# ATtiny15 register map
Vendor: Atmel; File version: 1.0
CPU: other r0p0, little endian, no MPU, no FPU, 4 interrupt priority bits
Registers are 8-bit, read-write, reset 0x0 unless marked. A register's access mark holds for its fields unless they carry their own. Offsets are from the block's base; lines under a group give offsets from that group; [hi:lo] are bit positions; {n}, {i} and the like mark numbered series; 'fields as' and 'values as' point back to an identical list; <NAME> marks a mode.

## Memory map
0x00800004 ADC size 0x4 — Analog-to-Digital Converter
0x00800008 AC size 0x1 — Analog Comparator
0x00800016 PORTB size 0x3 — I/O Port
0x0080001C EEPROM size 0x3
0x00800021 WDT size 0x1 — Watchdog Timer
0x0080002C TC1 blocks up to offset 0xE — Timer/Counter, 8-bit
0x00800031 CPU blocks up to offset 0xF — CPU Registers
0x00800032 TC0 blocks up to offset 0x8 — Timer/Counter, 8-bit
0x0080003A EXINT size 0x2 — External Interrupts

## Interrupts
0 RESET (CPU) — External Reset, Power-on Reset and Watchdog Reset
1 INT0 (CPU) — External Interrupt 0
2 IO_PINS (CPU) — External Interrupt Request 0
3 TIMER1_COMP (CPU) — Timer/Counter1 Compare Match
4 TIMER1_OVF (CPU) — Timer/Counter1 Overflow
5 TIMER0_OVF (CPU) — Timer/Counter0 Overflow
6 EE_RDY (CPU) — EEPROM Ready
7 ANA_COMP (CPU) — Analog Comparator
8 ADC (CPU) — ADC Conversion Ready

## AC — Analog Comparator
Base 0x00800008
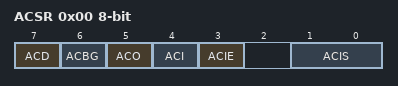
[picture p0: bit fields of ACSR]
0x00 ACSR — Analog Comparator Control And Status Register
  [7] ACD — Analog Comparator Disable
  [6] ACBG — Analog Comparator Bandgap Select
  [5] ACO — Analog Compare Output
  [4] ACI — Analog Comparator Interrupt Flag
  [3] ACIE — Analog Comparator Interrupt Enable
  [1:0] ACIS — Analog Comparator Interrupt Mode Select bits
    0=INTERRUPT_ON_TOGGLE; 2=INTERRUPT_ON_FALLING_EDGE; 3=INTERRUPT_ON_RISING_EDGE

## ADC — Analog-to-Digital Converter
Base 0x00800004
0x00 ADC 16-bit (reset mask 0xFF) — ADC Data Register Bytes
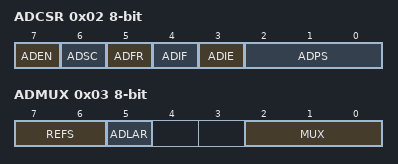
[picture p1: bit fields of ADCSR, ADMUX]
0x02 ADCSR — The ADC Control and Status register
  [7] ADEN — ADC Enable
  [6] ADSC — ADC Start Conversion
  [5] ADFR — ADC Free Running Select
  [4] ADIF — ADC Interrupt Flag
  [3] ADIE — ADC Interrupt Enable
  [2:0] ADPS — ADC Prescaler Select Bits
    1=2; 2=4; 3=8; 4=16; 5=32; 6=64; 7=128
0x03 ADMUX — The ADC multiplexer Selection Register
  [7:6] REFS — Reference Selection Bits
    0=AVCC; 1=AREF; 2=INTERNAL_VOLTAGE_REFERANCE (Internal Voltage Reference); 3=INTERNAL_VOLTAGE_REFERENCE_WITH_EXTERNAL_CAPACITOR_AT_AREF_PIN
  [5] ADLAR — Left Adjust Result
  [2:0] MUX — Analog Channel and Gain Selection Bits

## CPU — CPU Registers
Base 0x00800031
0x00 OSCCAL — Status Register
  [7:0] OSCCAL — Oscillator Calibration
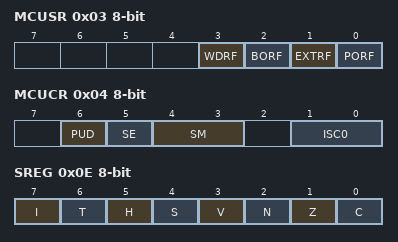
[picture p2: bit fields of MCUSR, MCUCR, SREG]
0x03 MCUSR — MCU Status register
  [3] WDRF — Watchdog Reset Flag
  [2] BORF — Brown-out Reset Flag
  [1] EXTRF — External Reset Flag
  [0] PORF — Power-On Reset Flag
0x04 MCUCR — MCU Control Register
  [6] PUD — Pull-up Disable
  [5] SE — Sleep Enable
  [4:3] SM — Sleep Mode Select Bits
    0=IDLE; 1=ADC (ADC Noise Reduction (If Available)); 2=PDOWN (Power Down)
  [1:0] ISC0 — Interrupt Sense Control 0 bits
    0=LOW_LEVEL_OF_INTX; 1=ANY_LOGICAL_CHANGE_IN_INTX; 2=FALLING_EDGE_OF_INTX; 3=RISING_EDGE_OF_INTX
0x0E SREG — Status Register
  [7] I — Global Interrupt Enable
  [6] T — Bit Copy Storage
  [5] H — Half Carry Flag
  [4] S — Sign Bit
  [3] V — Two's Complement Overflow Flag
  [2] N — Negative Flag
  [1] Z — Zero Flag
  [0] C — Carry Flag

## EEPROM
Base 0x0080001C
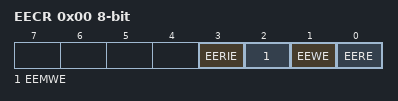
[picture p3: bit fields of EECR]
0x00 EECR — EEPROM Control Register
  [3] EERIE — EEProm Ready Interrupt Enable
  [2] EEMWE — EEPROM Master Write Enable
  [1] EEWE — EEPROM Write Enable
  [0] EERE — EEPROM Read Enable
0x01 EEDR — EEPROM Data Register
0x02 EEAR — EEPROM Read/Write Access

## EXINT — External Interrupts
Base 0x0080003A
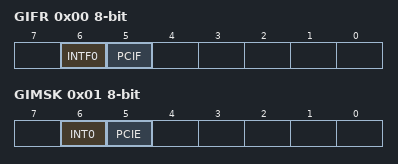
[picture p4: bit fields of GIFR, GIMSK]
0x00 GIFR — General Interrupt Flag register
  [6] INTF0 — External Interrupt Flag 0
  [5] PCIF — Pin Change Interrupt Flag
0x01 GIMSK — General Interrupt Mask Register
  [6] INT0 — External Interrupt Request 0 Enable
  [5] PCIE — Pin Change Interrupt Enable

## PORTB — I/O Port
Base 0x00800016
0x00 PINB — Input Pins, Port B
0x01 DDRB — Data Direction Register, Port B
0x02 PORTB — Data Register, Port B

## TC0 — Timer/Counter, 8-bit
Base 0x00800032
0x00 TCNT0 — Timer Counter 0
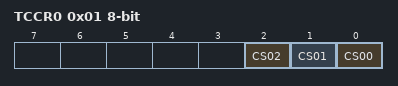
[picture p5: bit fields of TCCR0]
0x01 TCCR0 — Timer/Counter0 Control Register
  [2] CS02 — Clock Select0 bit 2
    0=NO_CLOCK_SOURCE_STOPPED; 1=RUNNING_NO_PRESCALING
  [1] CS01 — Clock Select0 bit 1
  [0] CS00 — Clock Select0 bit 0
0x06 TIFR — Timer/Counter Interrupt Flag register
  [1] TOV0 — Timer/Counter0 Overflow Flag
0x07 TIMSK — Timer/Counter Interrupt Mask Register
  [1] TOIE0 — Timer/Counter0 Overflow Interrupt Enable

## TC1 — Timer/Counter, 8-bit
Base 0x0080002C
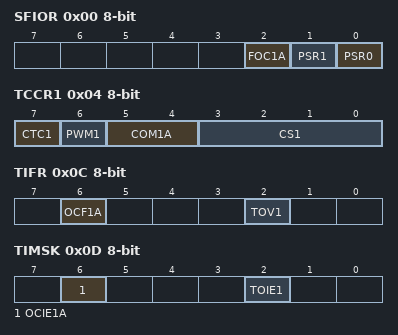
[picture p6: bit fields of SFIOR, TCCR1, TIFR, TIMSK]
0x00 SFIOR — Special Function IO Register
  [2] FOC1A — Force Output Compare 1A
  [1] PSR1 — Prescaler Reset Timer/Counter1
  [0] PSR0 — Prescaler Reset Timer/Counter0
0x01 OCR1B — Output Compare Register
0x02 OCR1A — Output Compare Register
0x03 TCNT1 — Timer/Counter Register
0x04 TCCR1 — Timer/Counter Control Register
  [7] CTC1 — Clear Timer/Counter on Compare Match
  [6] PWM1 — Pulse Width Modulator Enable
  [5:4] COM1A — Compare Output Mode, Bits
    0=DISCONNECTED_FROM_OCN_PWMN; 1=TOGGLE_OCN_PWMN_OUTPUT_LINE; 2=CLEAR_OCN_PWMN_OUTPUT_LINE; 3=SET_OCN_PWMN_OUTPUT_LINE
  [3:0] CS1 — Clock Select Bits
    0=NO_CLOCK_SOURCE_STOPPED; 5=RUNNING_NO_PRESCALING; 6=RUNNING_CLK_2; 7=RUNNING_CLK_4; 8=RUNNING_CLK_8; 9=RUNNING_CLK_16; 10=RUNNING_CLK_32; 11=RUNNING_CLK_64; 12=RUNNING_CLK_128; 13=RUNNING_CLK_256; 14=RUNNING_CLK_512; 15=RUNNING_CLK_1024
0x0C TIFR — Timer/Counter Interrupt Flag Register
  [6] OCF1A — Timer/Counter1 Output Compare Flag 1A
  [2] TOV1 — Timer/Counter1 Overflow Flag
0x0D TIMSK — Timer/Counter Interrupt Mask Register
  [6] OCIE1A — OCIE1A: Timer/Counter1 Output Compare Interrupt Enable
  [2] TOIE1 — Timer/Counter1 Overflow Interrupt Enable

## WDT — Watchdog Timer
Base 0x00800021
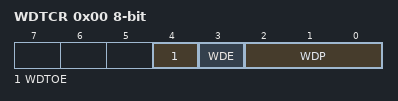
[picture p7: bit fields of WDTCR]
0x00 WDTCR — Watchdog Timer Control Register
  [4] WDTOE — RW
  [3] WDE — Watch Dog Enable
  [2:0] WDP — Watch Dog Timer Prescaler bits
    0=OSCILLATOR_CYCLES_16K; 1=OSCILLATOR_CYCLES_32K; 2=OSCILLATOR_CYCLES_64K; 3=OSCILLATOR_CYCLES_128K; 4=OSCILLATOR_CYCLES_256K; 5=OSCILLATOR_CYCLES_512K; 6=OSCILLATOR_CYCLES_1024K; 7=OSCILLATOR_CYCLES_2048K
